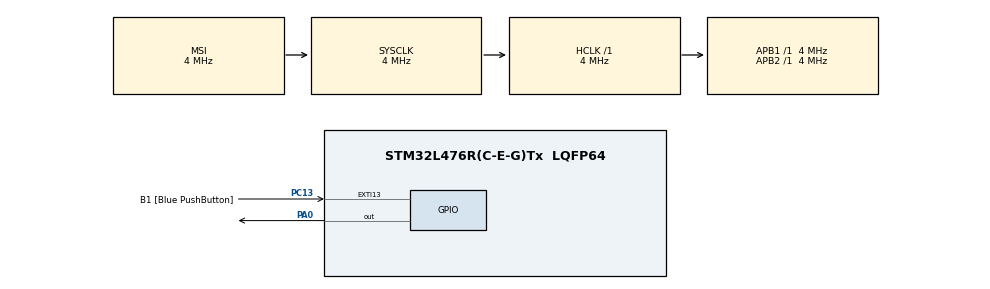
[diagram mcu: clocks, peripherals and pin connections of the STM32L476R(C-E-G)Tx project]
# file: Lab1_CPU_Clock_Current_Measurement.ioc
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Mcu.Family=STM32L4
Mcu.Name=STM32L476R(C-E-G)Tx
Mcu.Package=LQFP64
NVIC.EXTI15_10_IRQn=true\:0\:0\:false\:false\:true\:true\:true\:true
NVIC.PriorityGroup=NVIC_PRIORITYGROUP_4
PA0.GPIO_PuPd=GPIO_PULLUP
PA0.Signal=GPIO_Output
PA13\ (JTMS-SWDIO).GPIO_Label=TMS
PA13\ (JTMS-SWDIO).Mode=Serial_Wire
PA13\ (JTMS-SWDIO).Signal=SYS_JTMS-SWDIO
PA14\ (JTCK-SWCLK).GPIO_Label=TCK
PA14\ (JTCK-SWCLK).Mode=Serial_Wire
PA14\ (JTCK-SWCLK).Signal=SYS_JTCK-SWCLK
PC13.GPIO_Label=B1 [Blue PushButton]
PC13.GPIO_ModeDefaultEXTI=GPIO_MODE_IT_FALLING
PC13.GPIO_PuPd=GPIO_PULLUP
PC13.Signal=GPXTI13
PC14-OSC32_IN\ (PC14).Mode=LSE-External-Oscillator
PC14-OSC32_IN\ (PC14).Signal=RCC_OSC32_IN
PC15-OSC32_OUT\ (PC15).Mode=LSE-External-Oscillator
PC15-OSC32_OUT\ (PC15).Signal=RCC_OSC32_OUT
ProjectManager.HeapSize=0x200
ProjectManager.StackSize=0x400
ProjectManager.TargetToolchain=STM32CubeIDE
RCC.ADCFreq_Value=16000000
RCC.AHBFreq_Value=4000000
RCC.APB1Freq_Value=4000000
RCC.APB1TimFreq_Value=4000000
RCC.APB2Freq_Value=4000000
RCC.APB2TimFreq_Value=4000000
RCC.CortexFreq_Value=4000000
RCC.HCLKFreq_Value=4000000
RCC.HSE_VALUE=8000000
RCC.HSI_VALUE=16000000
RCC.MSI_VALUE=4000000
RCC.PLLN=10
RCC.PREFETCH_ENABLE=1
RCC.SYSCLKFreq_VALUE=4000000
RCC.USBFreq_Value=16000000
RCC.VCOOutputFreq_Value=40000000
board=NUCLEO-L476RG

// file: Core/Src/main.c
/* USER CODE BEGIN Header */
/**
  ******************************************************************************
  * @file           : main.c
  * @brief          : Main program body
  ******************************************************************************
  * @attention
  *
  * Copyright (c) 2023 STMicroelectronics.
  * All rights reserved.
  *
  * This software is licensed under terms that can be found in the LICENSE file
  * in the root directory of this software component.
  * If no LICENSE file comes with this software, it is provided AS-IS.
  *
  ******************************************************************************
  */
/* USER CODE END Header */
#include "main.h"

void SystemClock_Config(void);
static void MX_GPIO_Init(void);

/* USER CODE BEGIN 0 */
extern int blinkState;
/* USER CODE END 0 */

int main(void)
{

  /* MCU Configuration--------------------------------------------------------*/

  /* Reset of all peripherals, Initializes the Flash interface and the Systick. */
  HAL_Init();

  /* USER CODE BEGIN Init */
  //HAL_PWR_EnterSLEEPMode(PWR_MAINREGULATOR_ON,PWR_SLEEPENTRY_WFI);
  //HAL_PWR_EnterSLEEPMode(PWR_LOWPOWERREGULATOR_ON,PWR_SLEEPENTRY_WFI);
  //HAL_PWREx_EnterSTOP0Mode(PWR_STOPENTRY_WFI);
  //HAL_PWREx_EnterSTOP1Mode(PWR_STOPENTRY_WFI);
  //HAL_PWREx_EnterSTOP2Mode(PWR_STOPENTRY_WFI);
  //HAL_PWREx_EnterSHUTDOWNMode();
  /* USER CODE END Init */

  /* Configure the system clock */
  SystemClock_Config();

  /* Initialize all configured peripherals */
  MX_GPIO_Init();
  /* USER CODE BEGIN 2 */
  volatile int clkCount;
  /* USER CODE END 2 */

  /* Infinite loop */
  while (1){

    /* USER CODE BEGIN 3 */
	if(blinkState){
		clkCount = 400000;
		while(clkCount--);
		HAL_GPIO_TogglePin (GPIOA, GPIO_PIN_0);
	}
  }
  /* USER CODE END 3 */
}

void SystemClock_Config(void)
{
  RCC_OscInitTypeDef RCC_OscInitStruct = {0};
  RCC_ClkInitTypeDef RCC_ClkInitStruct = {0};

  /** Configure the main internal regulator output voltage
  */
  if (HAL_PWREx_ControlVoltageScaling(PWR_REGULATOR_VOLTAGE_SCALE1) != HAL_OK)
  {
    Error_Handler();
  }

  /** Configure LSE Drive Capability
  */
  HAL_PWR_EnableBkUpAccess();
  __HAL_RCC_LSEDRIVE_CONFIG(RCC_LSEDRIVE_LOW);

  /** Initializes the RCC Oscillators according to the specified parameters
  * in the RCC_OscInitTypeDef structure.
  */
  RCC_OscInitStruct.OscillatorType = RCC_OSCILLATORTYPE_LSE|RCC_OSCILLATORTYPE_MSI;
  RCC_OscInitStruct.LSEState = RCC_LSE_ON;
  RCC_OscInitStruct.MSIState = RCC_MSI_ON;
  RCC_OscInitStruct.MSICalibrationValue = 0;
  RCC_OscInitStruct.MSIClockRange = RCC_MSIRANGE_6;
  RCC_OscInitStruct.PLL.PLLState = RCC_PLL_NONE;
  if (HAL_RCC_OscConfig(&RCC_OscInitStruct) != HAL_OK)
  {
    Error_Handler();
  }

  /** Initializes the CPU, AHB and APB buses clocks
  */
  RCC_ClkInitStruct.ClockType = RCC_CLOCKTYPE_HCLK|RCC_CLOCKTYPE_SYSCLK
                              |RCC_CLOCKTYPE_PCLK1|RCC_CLOCKTYPE_PCLK2;
  RCC_ClkInitStruct.SYSCLKSource = RCC_SYSCLKSOURCE_MSI;
  RCC_ClkInitStruct.AHBCLKDivider = RCC_SYSCLK_DIV1;
  RCC_ClkInitStruct.APB1CLKDivider = RCC_HCLK_DIV1;
  RCC_ClkInitStruct.APB2CLKDivider = RCC_HCLK_DIV1;

  if (HAL_RCC_ClockConfig(&RCC_ClkInitStruct, FLASH_LATENCY_0) != HAL_OK)
  {
    Error_Handler();
  }

  /** Enable MSI Auto calibration
  */
  HAL_RCCEx_EnableMSIPLLMode();
}

static void MX_GPIO_Init(void)
{
  GPIO_InitTypeDef GPIO_InitStruct = {0};

  /* GPIO Ports Clock Enable */
  __HAL_RCC_GPIOC_CLK_ENABLE();
  __HAL_RCC_GPIOA_CLK_ENABLE();

  /*Configure GPIO pin Output Level */
  HAL_GPIO_WritePin(GPIOA, GPIO_PIN_0, GPIO_PIN_RESET);

  /*Configure GPIO pin : B1_Pin */
  GPIO_InitStruct.Pin = B1_Pin;
  GPIO_InitStruct.Mode = GPIO_MODE_IT_FALLING;
  GPIO_InitStruct.Pull = GPIO_PULLUP;
  HAL_GPIO_Init(B1_GPIO_Port, &GPIO_InitStruct);

  /*Configure GPIO pin : PA0 */
  GPIO_InitStruct.Pin = GPIO_PIN_0;
  GPIO_InitStruct.Mode = GPIO_MODE_OUTPUT_PP;
  GPIO_InitStruct.Pull = GPIO_PULLUP;
  GPIO_InitStruct.Speed = GPIO_SPEED_FREQ_LOW;
  HAL_GPIO_Init(GPIOA, &GPIO_InitStruct);

  /* EXTI interrupt init*/
  HAL_NVIC_SetPriority(EXTI15_10_IRQn, 0, 0);
  HAL_NVIC_EnableIRQ(EXTI15_10_IRQn);

}

void Error_Handler(void)
{
  __disable_irq();
  while (1)
  {
  }
}
